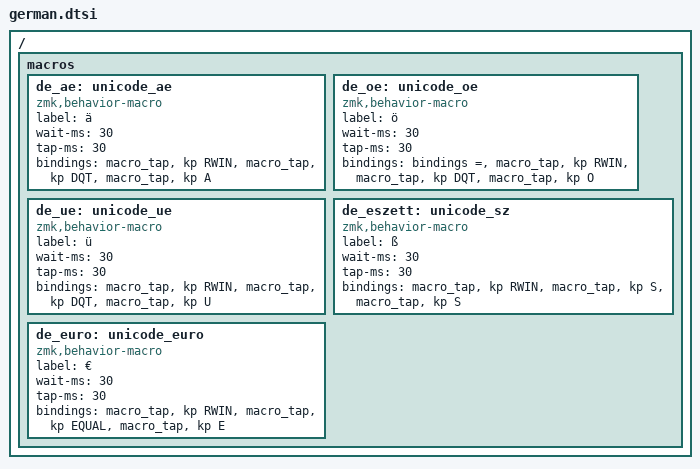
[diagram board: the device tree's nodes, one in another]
/ {
   macros {
      de_ae: unicode_ae {
         compatible = "zmk,behavior-macro";
         label = "ä";
         #binding-cells = <0>;
         wait-ms = <30>;
         tap-ms = <30>;
         bindings = <
            &macro_tap &kp RWIN
            &macro_tap &kp DQT
            &macro_tap &kp A
         >;
      };

      de_oe: unicode_oe {
         compatible = "zmk,behavior-macro";
         label = "ö";
         #binding-cells = <0>;
         wait-ms = <30>;
         tap-ms = <30>;
         bindings = <
         bindings = <
            &macro_tap &kp RWIN
            &macro_tap &kp DQT
            &macro_tap &kp O
         >;
      };

      de_ue: unicode_ue {
         compatible = "zmk,behavior-macro";
         label = "ü";
         #binding-cells = <0>;
         wait-ms = <30>;
         tap-ms = <30>;
         bindings = <
            &macro_tap &kp RWIN
            &macro_tap &kp DQT
            &macro_tap &kp U
         >;

      };

      de_eszett: unicode_sz {
         compatible = "zmk,behavior-macro";
         label = "ß";
         #binding-cells = <0>;
         wait-ms = <30>;
         tap-ms = <30>;
         bindings = <
            &macro_tap &kp RWIN
            &macro_tap &kp S
            &macro_tap &kp S
         >;
      };

      de_euro: unicode_euro {
         compatible = "zmk,behavior-macro";
         label = "€";
         #binding-cells = <0>;
         wait-ms = <30>;
         tap-ms = <30>;
         bindings = <
            &macro_tap &kp RWIN
            &macro_tap &kp EQUAL
            &macro_tap &kp E
         >;
      };
   };
};
